# PIC32CM5112GC00048 register map
Vendor: Microchip Technology; Series: PIC32CMGC00; File version: 0
CPU: CM23 r0p0, little endian, MPU, no FPU, 2 interrupt priority bits, 141 interrupts
Registers are 32-bit, read-write, reset 0x0 unless marked. A register's access mark holds for its fields unless they carry their own. Offsets are from the block's base; [hi:lo] are bit positions; lines under a group give offsets from that group; {n}, {i} and the like mark numbered series; 'fields as' and 'values as' point back to an identical list.

## PAC — Peripheral Access Controller
Base 0x44022000
0x00 CTRLA — Control A Register
  [2] PRIV — Privileged Access Only
    0=DISABLE (Macro register accessible in privileged and unprivileged accesses.); 1=ENABLE (Macro registers only accessible in privileged accesses)
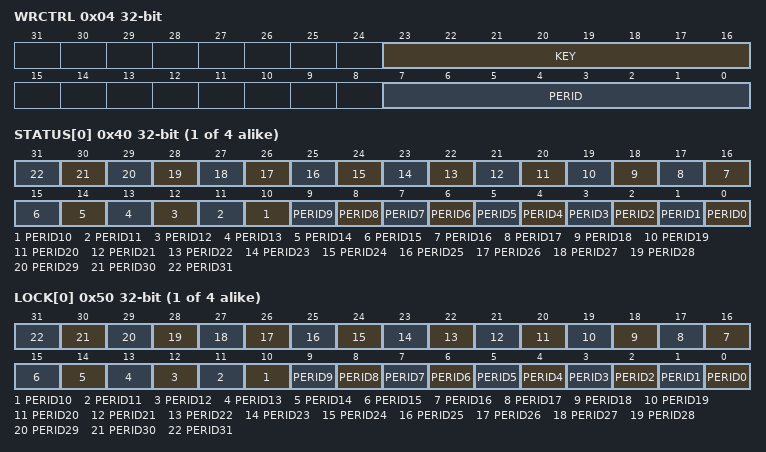
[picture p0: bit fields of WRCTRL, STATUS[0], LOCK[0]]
0x04 WRCTRL wo — Write Control Register
  [23:16] KEY — Peripheral Access Control Key
    0=OFF (OFF - No Action); 1=CLEAR (CLEAR - Clear the peripheral write protection); 2=SET (SET - Set the peripheral write protection); 3=LOCK (LOCK - Set and Lock the write protection state of the peripheral until the next reset)
  [7:0] PERID — Peripheral Identifier
{0x40+4i} STATUS[{i}] (i=0..3) ro — Peripheral Status n Register
  [all] fields
    0=Write Protection disabled; 1=Write Protection enabled
  [n] PERID{n} (n=0..31) — PERID Write Protection Status
{0x50+4i} LOCK[{i}] (i=0..3) ro — Peripheral Lock n Register
  [all] fields
    0=Write Protection Unlocked; 1=Write Protection Locked
  [n] PERID{n} (n=0..31) — PERID Write Protection Lock Status

## PM — Power Manager
Base 0x45000000
0x00 CTRLA 8-bit — Control A
  [2] IORET — I/O Retention
    0=NOIORET (When the device exits the HIBERNATE or BACKUP mode, the I/O line configuration are released.); 1=IORET (When the device exits the HIBERNATE or BACKUP mode, the I/O line configuration are stretched.)
0x01 SLEEPCFG 8-bit reset 0x2 — Sleep Configuration
  [2:0] SLEEPMODE
    2=IDLE (CPU, AHB and APB clocks are OFF); 4=STANDBY (All Clocks are OFF); 5=HIBERNATE (Backup domain is ON as well as some PDRAMs); 6=BACKUP (Only Backup domain is powered ON); 7=OFF (All power domains are powered OFF)
0x04 INTENCLR 8-bit — Interrupt Enable Clear
  [0] SLEEPRDY — Backup Sleep Mode Entry Ready Enable
0x05 INTENSET 8-bit — Interrupt Enable Set
  [0] SLEEPRDY — Backup Sleep Mode Entry Ready Enable
0x06 INTFLAG 8-bit — Interrupt Flag Status and Clear
  [0] SLEEPRDY — Backup Sleep Mode Entry Ready
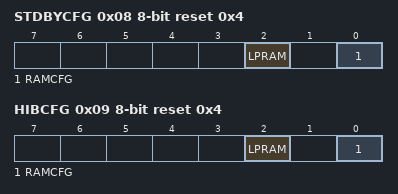
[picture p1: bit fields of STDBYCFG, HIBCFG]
0x08 STDBYCFG 8-bit reset 0x4 — Standby Configuration
  [2] LPRAM — Low Power RAM Enable
  [0] RAMCFG — Ram Configuration
    0=RET (All the RAMs are retained); 1=OFF (Only the first 32K bytes are retained)
0x09 HIBCFG 8-bit reset 0x4 — Hibernate Configuration
  fields as STDBYCFG

## PORT — Port Module
Base 0x44800000
{0x0+0x80*i} GROUP[{i}] (i=0..3) group
  0x00 DIR — Data Direction
    [31:0] DIR — Port Data Direction
  0x04 DIRCLR — Data Direction Clear
    [31:0] DIRCLR — Port Data Direction Clear
  0x08 DIRSET — Data Direction Set
    [31:0] DIRSET — Port Data Direction Set
  0x0C DIRTGL — Data Direction Toggle
    [31:0] DIRTGL — Port Data Direction Toggle
  0x10 OUT — Data Output Value
    [31:0] OUT — PORT Data Output Value
  0x14 OUTCLR — Data Output Value Clear
    [31:0] OUTCLR — PORT Data Output Value Clear
  0x18 OUTSET — Data Output Value Set
    [31:0] OUTSET — PORT Data Output Value Set
  0x1C OUTTGL — Data Output Value Toggle
    [31:0] OUTTGL — PORT Data Output Value Toggle
  0x20 IN ro — Data Input Value
    [31:0] IN — PORT Data Input Value
  0x24 CTRL — Control
    [31:0] SAMPLING — Input Sampling Mode
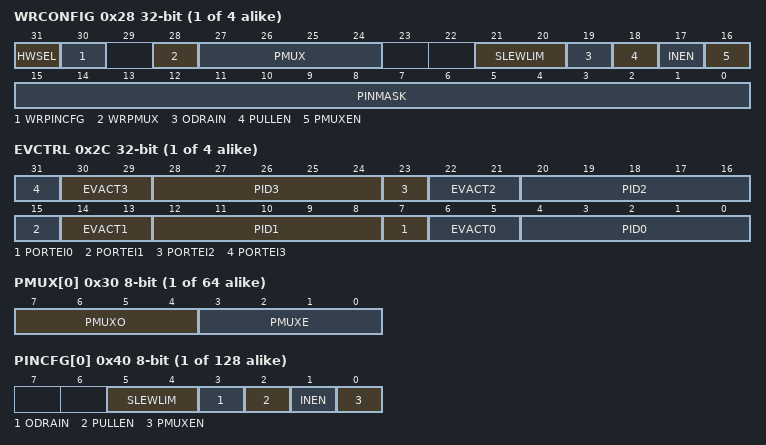
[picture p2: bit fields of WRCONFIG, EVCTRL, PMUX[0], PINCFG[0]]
  0x28 WRCONFIG wo — Write Configuration
    [31] HWSEL — Half-Word Select
    [30] WRPINCFG — Write PINCFG
    [28] WRPMUX — Write PMUX
    [27:24] PMUX — Peripheral Multiplexing
    [21:20] SLEWLIM — Output Driver Slew Rate Selection
    [19] ODRAIN — Open Drain Output
    [18] PULLEN — Pull Enable
    [17] INEN — Input Enable
    [16] PMUXEN — Peripheral Multiplexer Enable
    [15:0] PINMASK — Pin Mask for Multiple Pin Configuration
  0x2C EVCTRL — Event Input Control
    [8n+7] PORTEI{n} (n=0..3) — PORT Event Input Enable {n}
    [30:29] EVACT3 — PORT Event Action 3
    [8n+4:8n] PID{n} (n=0..3) — PORT Event Pin Identifier {n}
    [22:21] EVACT2 — PORT Event Action 2
    [14:13] EVACT1 — PORT Event Action 1
    [6:5] EVACT0 — PORT Event Action 0
      0=OUT (Event output to pin); 1=SET (Set output register of pin on event); 2=CLR (Clear output register of pin on event); 3=TGL (Toggle output register of pin on event)
  {0x30+j} PMUX[{j}] (j=0..15) 8-bit — Peripheral Multiplexing
    [7:4] PMUXO — Peripheral Multiplexing for Odd-Numbered Pin
      0=A (Peripheral function A selected); 1=B (Peripheral function B selected); 3=D (Peripheral function D selected); 5=F (Peripheral function F selected); 7=H (Peripheral function H selected); 8=I (Peripheral function I selected); 10=K (Peripheral function K selected); 15=P (Peripheral function P selected)
    [3:0] PMUXE — Peripheral Multiplexing for Even-Numbered Pin
      values as PMUXO
  {0x40+j} PINCFG[{j}] (j=0..31) 8-bit — Pin Configuration
    [5:4] SLEWLIM — Output Driver Slew Rate Selection
      0=FAST (Slew rate control disabled (fast rise/fall time operation)); 1=SLOW4 (Slew rate control enabled (4x slower)); 2=SLOW8 (Slew rate control enabled (8x slower)); 3=SLOW12 (Slew rate control enabled (12x slower))
    [3] ODRAIN — Open Drain Output
    [2] PULLEN — Pull Enable
    [1] INEN — Input Enable
    [0] PMUXEN — Peripheral Multiplexer Enable
  0x60 INTENCLR — Interrupt Enable Clear
    [0] NSCHK — Non-Secure Check Interrupt Enable
  0x64 INTENSET — Interrupt Enable Set
    [0] NSCHK — Non-Secure Check Interrupt Enable
  0x68 INTFLAG — Interrupt Flag Status and Clear
    [0] NSCHK — Non-Secure Check
  0x6C NONSEC — Security Attribution
    [31:0] NONSEC — Port Security Attribution
  0x70 NSCHK — Security Attribution Check
    [31:0] NSCHK — Port Security Attribution Check

## RSTC — Reset Controller
Base 0x45004000
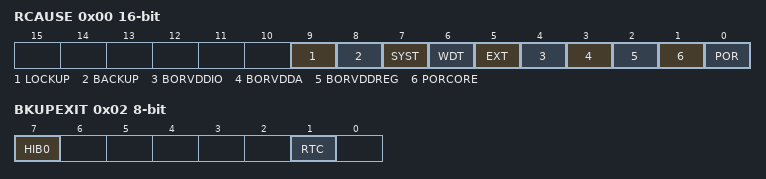
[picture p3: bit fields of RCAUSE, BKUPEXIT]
0x00 RCAUSE 16-bit ro — Reset Cause
  [9] LOCKUP — Lockup Reset
  [8] BACKUP — Backup Reset
  [7] SYST — System Reset Request
  [6] WDT — Watchdog Reset
  [5] EXT — External Reset
  [4] BORVDDIO — Brown Out VDDIO Detector Reset
  [3] BORVDDA — Brown Out VDDA Detector Reset
  [2] BORVDDREG — Brown Out VDDREG Detector Reset
  [1] PORCORE — Brown Out CORE Detector Reset
  [0] POR — Power On Reset
0x02 BKUPEXIT 8-bit ro — Backup Exit Source. Implemented only if RSTC_BACKUP_IMPLEMENTED=1
  [7] HIB0 — Hibernate
  [1] RTC — Real Timer Counter Interrupt
0x04 DBGCTRL — Debug Control
  [0] LCKUPDIS — Lockup Disable

## SAU — Security Attribution Unit
Base 0xE000EDD0
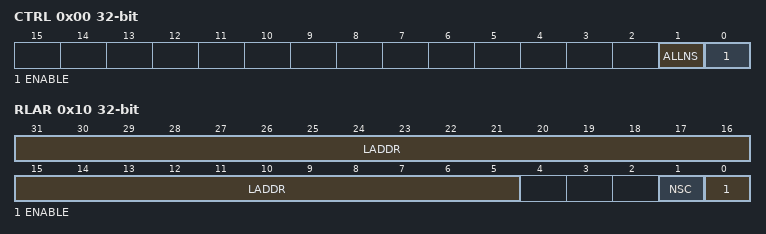
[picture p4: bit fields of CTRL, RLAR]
0x00 CTRL — SAU Control Register
  [1] ALLNS — All Non-secure
  [0] ENABLE — SAU enable
0x04 TYPE ro — SAU Type Register
  [7:0] SREGION — Number of SAU regions
0x08 RNR — SAU Region Number Register
  [7:0] REGION — Selected SAU region number
0x0C RBAR — SAU Region Base Address Register
  [31:5] BADDR — Base address
0x10 RLAR — SAU Region Limit Address Register
  [31:5] LADDR — Limit address
  [1] NSC — Non-secure callable region
  [0] ENABLE — SAU region enable

## SysTick — SysTick Timer
Base 0xE000E010
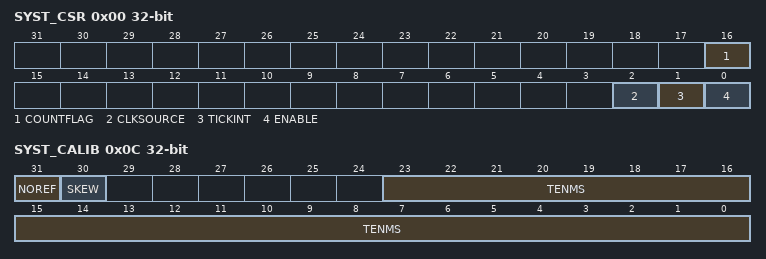
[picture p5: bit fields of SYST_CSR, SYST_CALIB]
0x00 SYST_CSR — SysTick Control and Status Register
  [16] COUNTFLAG
  [2] CLKSOURCE — Clock source
  [1] TICKINT — Tick interrupt
  [0] ENABLE — SysTick enable
0x04 SYST_RVR — SysTick Reload Value Register
  [24] RELOAD — Counter reload value
0x08 SYST_CVR — SysTick Current Value Register
  [24] CURRENT — Current counter value
0x0C SYST_CALIB ro — SysTick Calibration Value Register
  [31] NOREF — No reference
  [30] SKEW
  [23:0] TENMS — Ten milliseconds

## WDT — Watchdog Timer
Base 0x4400E000
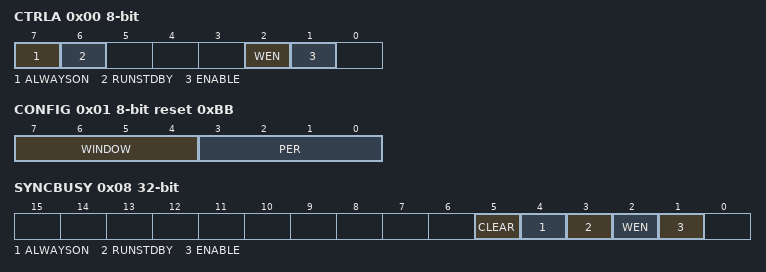
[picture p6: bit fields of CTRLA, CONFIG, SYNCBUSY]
0x00 CTRLA 8-bit — Control
  [7] ALWAYSON
  [6] RUNSTDBY — Run During Standby
  [2] WEN — Watchdog Timer Window Mode Enable
  [1] ENABLE
0x01 CONFIG 8-bit reset 0xBB — Configuration
  [7:4] WINDOW — Window Mode Time-Out Period
    0=CYC8 (8 clock cycles); 1=CYC16 (16 clock cycles); 2=CYC32 (32 clock cycles); 3=CYC64 (64 clock cycles); 4=CYC128 (128 clock cycles); 5=CYC256 (256 clock cycles); 6=CYC512 (512 clock cycles); 7=CYC1024 (1024 clock cycles); 8=CYC2048 (2048 clock cycles); 9=CYC4096 (4096 clock cycles); 10=CYC8192 (8192 clock cycles); 11=CYC16384 (16384 clock cycles)
  [3:0] PER — Time-Out Period
    values as WINDOW
0x02 EWCTRL 8-bit reset 0xB — Early Warning Interrupt Control
  [3:0] EWOFFSET — Early Warning Interrupt Time Offset
    values as CONFIG.WINDOW
0x04 INTENCLR 8-bit — Interrupt Enable Clear
  [0] EW — Early Warning Interrupt Enable
0x05 INTENSET 8-bit — Interrupt Enable Set
  [0] EW — Early Warning Interrupt Enable
0x06 INTFLAG 8-bit — Interrupt Flag Status and Clear
  [0] EW — Early Warning
0x08 SYNCBUSY ro — Synchronization Busy
  [5] CLEAR — Clear Synchronization Busy
  [4] ALWAYSON — Always-On Synchronization Busy
  [3] RUNSTDBY — Run During Standby Synchronization Busy
  [2] WEN — Window Enable Synchronization Busy
  [1] ENABLE — Enable Synchronization Busy
0x0C CLEAR 8-bit wo
  [7:0] CLEAR — Watchdog Clear
    165=KEY (Clear Key)

## Notices in the file
Copyright (c) 2025 Microchip Technology Inc.
SPDX-License-Identifier: Apache-2.0
Licensed under the Apache License, Version 2.0 (the "License");
you may not use this file except in compliance with the License.
You may obtain a copy of the License at
http://www.apache.org/licenses/LICENSE-2.0
Unless required by applicable law or agreed to in writing, software
distributed under the License is distributed on an "AS IS" BASIS,
WITHOUT WARRANTIES OR CONDITIONS OF ANY KIND, either express or implied.
See the License for the specific language governing permissions and
limitations under the License.
